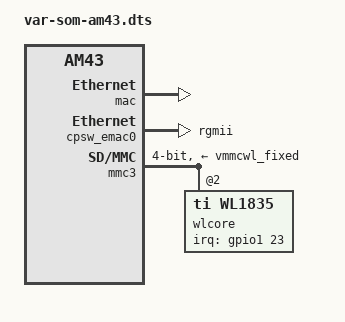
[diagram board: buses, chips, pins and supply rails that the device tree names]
/*
 * Copyright (C) 2014 Variscite LTD - http://www.variscite.com/
 *
 * This program is free software; you can redistribute it and/or modify
 * it under the terms of the GNU General Public License version 2 as
 * published by the Free Software Foundation.
 */

/* VAR-SOM-AM43 */

#include "var-som-am43.dtsi"

&am43xx_pinmux {
	mmc3_pins_default: pinmux_mmc3_pins_default {
		pinctrl-single,pins = <
			0x44 (PIN_INPUT_PULLUP | MUX_MODE3)      /* gpmc_a1.mmc2_dat0 */
			0x48 (PIN_INPUT_PULLUP | MUX_MODE3)      /* gpmc_a2.mmc2_dat1 */
			0x4c (PIN_INPUT_PULLUP | MUX_MODE3)      /* gpmc_a3.mmc2_dat2 */
			0x78 (PIN_INPUT_PULLUP | MUX_MODE3)      /* gpmc_be1n.mmc2_dat3 */
			0x8c (PIN_INPUT_PULLUP | MUX_MODE3)      /* gpmc_clk.mmc2_clk */
			0x88 (PIN_INPUT_PULLUP | MUX_MODE3)      /* gpmc_csn3.mmc2_cmd */
		>;
	};

	mmc3_pins_sleep: pinmux_mmc3_pins_sleep {
		pinctrl-single,pins = <
			0x44 (PIN_INPUT_PULLDOWN | MUX_MODE7)	/* gpmc_a1.mmc2_dat0 */
			0x48 (PIN_INPUT_PULLDOWN | MUX_MODE7)	/* gpmc_a2.mmc2_dat1 */
			0x4c (PIN_INPUT_PULLDOWN | MUX_MODE7)	/* gpmc_a3.mmc2_dat2 */
			0x78 (PIN_INPUT_PULLDOWN | MUX_MODE7)	/* gpmc_be1n.mmc2_dat3 */
			0x8c (PIN_INPUT_PULLDOWN | MUX_MODE7)	/* gpmc_clk.mmc2_clk */
			0x88 (PIN_INPUT_PULLDOWN | MUX_MODE7)	/* gpmc_csn3.mmc2_cmd */
		>;
	};

	wlan_pins_default: pinmux_wlan_pins_default {
		pinctrl-single,pins = <
			0x50 (PIN_OUTPUT_PULLDOWN | MUX_MODE7)		/* gpmc_a4.gpio1_20 WL_EN */
			0x5c (PIN_INPUT | WAKEUP_ENABLE | MUX_MODE7)	/* gpmc_a7.gpio1_23 WL_IRQ*/
			0x40 (PIN_OUTPUT_PULLDOWN | MUX_MODE7)		/* gpmc_a0.gpio1_16 BT_EN*/
			
			0x6c (PIN_INPUT_PULLDOWN | MUX_MODE7)   /* gpmc_a11.mcasp0_axr1 COM_AUD_OUT */
			0x68 (PIN_INPUT_PULLDOWN | MUX_MODE7)   /* gpmc_a10.mcasp0_axr1 COM_AUD_IN  */
			0x64 (PIN_INPUT_PULLDOWN | MUX_MODE7)   /* gpmc_a9.mcasp0_fsx   COM_AUD_FSYNC */
			0x60 (PIN_INPUT_PULLDOWN | MUX_MODE7)   /* gpmc_a8.mcasp0_aclkx COM_AUD_CLK */		
		>;
	};

	wlan_pins_sleep: pinmux_wlan_pins_sleep {
		pinctrl-single,pins = <
			0x50 (PIN_OUTPUT_PULLDOWN | MUX_MODE7)		/* gpmc_a4.gpio1_20 WL_EN */
			0x5c (PIN_INPUT | WAKEUP_ENABLE | MUX_MODE7)	/* gpmc_a7.gpio1_23 WL_IRQ*/
			0x40 (PIN_OUTPUT_PULLUP | MUX_MODE7)		/* gpmc_a0.gpio1_16 BT_EN*/
						
			0x6c (PIN_INPUT | MUX_MODE7)   /* gpmc_a11.mcasp0_axr1 COM_AUD_OUT */
			0x68 (PIN_INPUT | MUX_MODE7)   /* gpmc_a10.mcasp0_axr1 COM_AUD_IN  */
			0x64 (PIN_INPUT | MUX_MODE7)   /* gpmc_a9.mcasp0_fsx   COM_AUD_FSYNC */
			0x60 (PIN_INPUT | MUX_MODE7)   /* gpmc_a8.mcasp0_aclkx COM_AUD_CLK */		
		>;
	};
};

&mac {
	slaves = <1>;
	pinctrl-names = "default", "sleep";
	pinctrl-0 = <&cpsw_default>;
	pinctrl-1 = <&cpsw_sleep>;
	status = "okay";
};

&cpsw_emac0 {
	phy_id = <&davinci_mdio>, <0>;
	phy-mode = "rgmii";
};

&mmc3 { /* WL8 */
	status = "okay";
	/* these are on the crossbar and are outlined in the
	   xbar-event-map element */
	dmas = <&edma_xbar 30 0 1>,
		<&edma_xbar 31 0 2>;	
	dma-names = "tx", "rx";
	vmmc-supply = <&vmmcwl_fixed>;
	bus-width = <4>;
	pinctrl-names = "default", "sleep";
	pinctrl-0 = <&mmc3_pins_default &wlan_pins_default>;
	pinctrl-1 = <&mmc3_pins_sleep &wlan_pins_sleep>;
	cap-power-off-card;
	keep-power-in-suspend;	
	ti,non-removable;

	#address-cells = <1>;
	#size-cells = <0>;
	wlcore: wlcore@0 {
		compatible = "ti,wl1835";
		reg = <2>;
		interrupt-parent = <&gpio1>;
		interrupts = <23 IRQ_TYPE_LEVEL_HIGH>;
	};
};


